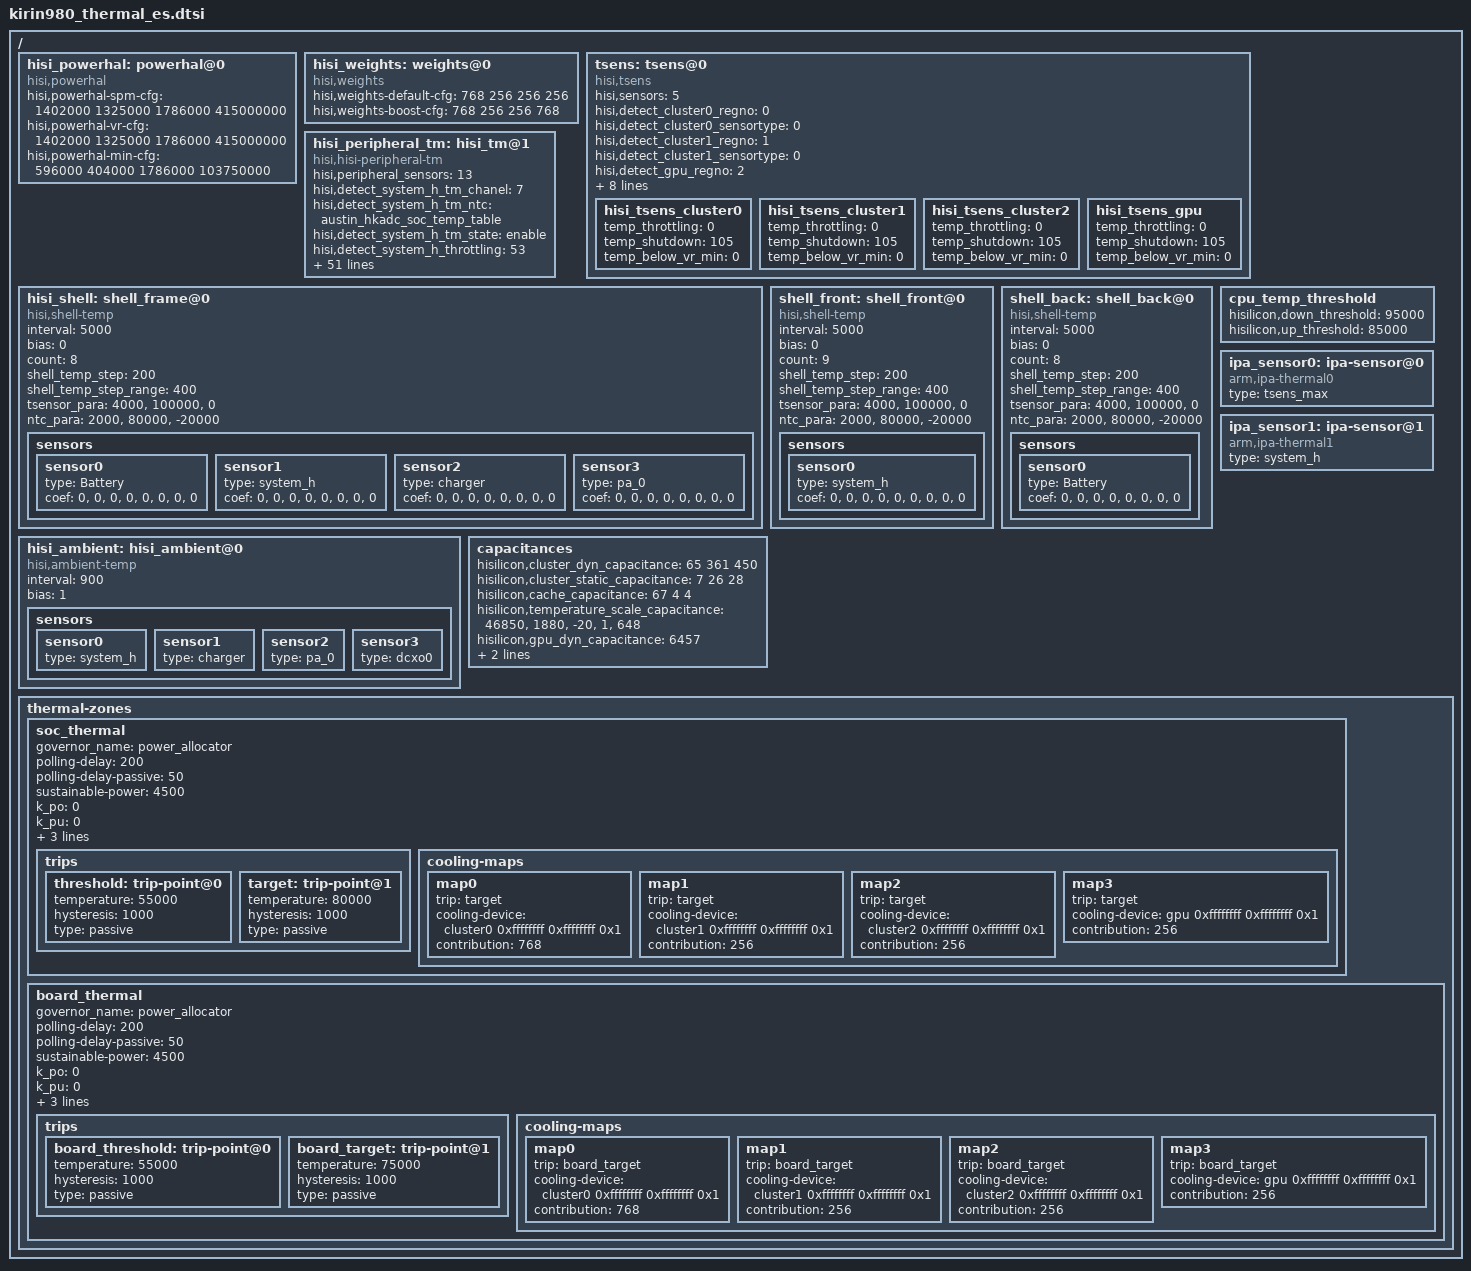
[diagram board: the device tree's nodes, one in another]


  /{
		hisi_powerhal: powerhal@0 {
			compatible = "hisi,powerhal";
			/*CPU_L, CPU_M, CPU_B, GPU*/
			hisi,powerhal-spm-cfg = <1402000 1325000 1786000 415000000>;
			hisi,powerhal-vr-cfg = <1402000 1325000 1786000 415000000>;
			hisi,powerhal-min-cfg = <596000 404000 1786000 103750000>;
		};

		hisi_weights: weights@0 {
			compatible = "hisi,weights";
			/*IPA_CLUSTER0, IPA_CLUSTER1, IPA_CLUSTER2, GPU*/
			hisi,weights-default-cfg = <768 256 256 256>;
			hisi,weights-boost-cfg = <768 256 256 768>;
		};

		tsens: tsens@0{
			compatible = "hisi,tsens";
			hisi,sensors = <5>;
			/*sensortype, 0:Tsensor, 1:PVTsensor */
			hisi,detect_cluster0_regno = <0>;
			hisi,detect_cluster0_sensortype = <0>;
			hisi,detect_cluster1_regno = <1>;
			hisi,detect_cluster1_sensortype = <0>;
			hisi,detect_gpu_regno = <2>;
			hisi,detect_gpu_sensortype = <1>;
			hisi,detect_modem_regno = <3>;
			hisi,detect_modem_sensortype = <0>;
			hisi,detect_ddr_regno = <0xff>;
			hisi,tsensor_adc_start_value = <109>;
			hisi,tsensor_adc_end_value = <907>;
			hisi,pvtsensor_adc_start_value = <500>;
			hisi,pvtsensor_adc_end_value = <851>;
			hisi_tsens_cluster0 {
				temp_throttling = <0>;
				temp_shutdown = <105>;
				temp_below_vr_min = <0>;
			};

			hisi_tsens_cluster1 {
				temp_throttling = <0>;
				temp_shutdown = <105>;
				temp_below_vr_min = <0>;
			};
			hisi_tsens_cluster2 {
				temp_throttling = <0>;
				temp_shutdown = <105>;
				temp_below_vr_min = <0>;
			};
			hisi_tsens_gpu {
				temp_throttling = <0>;
				temp_shutdown = <105>;
				temp_below_vr_min = <0>;
			};
		};

		hisi_peripheral_tm: hisi_tm@1 {
			compatible = "hisi,hisi-peripheral-tm";
			hisi,peripheral_sensors = <13>;

			hisi,detect_system_h_tm_chanel = <7>;
			hisi,detect_system_h_tm_ntc = "austin_hkadc_soc_temp_table";
			hisi,detect_system_h_tm_state = "enable";
			hisi,detect_system_h_throttling = <53>;
			hisi,detect_system_h_shutdown = <55>;
			hisi,detect_system_h_below_vr_min = <53>;
			hisi,detect_system_h_over_skin = <12>;

			hisi,detect_flash_led_tm_chanel = <13>;
			hisi,detect_flash_led_tm_ntc = "austin_hkadc_soc_temp_table";
			hisi,detect_flash_led_tm_state = "enable";

			hisi,detect_charger_tm_chanel = <4>;
			hisi,detect_charger_tm_ntc = "austin_hkadc_soc_temp_table";
			hisi,detect_charger_tm_state = "enable";

			hisi,detect_pa_0_tm_chanel = <5>;
			hisi,detect_pa_0_tm_ntc = "austin_hkadc_pa_temp_table";
			hisi,detect_pa_0_tm_state = "enable";

			hisi,detect_pa_1_tm_chanel = <6>;
			hisi,detect_pa_1_tm_ntc = "austin_hkadc_pa_temp_table";
			hisi,detect_pa_1_tm_state = "enable";

			hisi,detect_dcxo0_tm_chanel = <15>;
			hisi,detect_dcxo0_tm_ntc = "austin_hkadc_adc_temp_table";
			hisi,detect_dcxo0_tm_state = "enable";

			hisi,detect_shell_tm_chanel = <7>;
			hisi,detect_shell_tm_ntc = "austin_hkadc_soc_temp_table";
			hisi,detect_shell_tm_state = "disable";

			hisi,detect_charger1_tm_chanel = <4>;
			hisi,detect_charger1_tm_ntc = "austin_hkadc_soc_temp_table";
			hisi,detect_charger1_tm_state = "disable";

			hisi,detect_rfboard_tm_chanel = <0>;
			hisi,detect_rfboard_tm_ntc = "austin_hkadc_soc_temp_table";
			hisi,detect_rfboard_tm_state = "disable";

			hisi,detect_usb_tm_chanel = <0>;
			hisi,detect_usb_tm_ntc = "austin_hkadc_soc_temp_table";
			hisi,detect_usb_tm_state = "disable";

			hisi,detect_wireless_tm_chanel = <0>;
			hisi,detect_wireless_tm_ntc = "austin_hkadc_soc_temp_table";
			hisi,detect_wireless_tm_state = "disable";

			hisi,detect_ir_tm_chanel = <0>;
			hisi,detect_ir_tm_ntc = "austin_hkadc_soc_temp_table";
			hisi,detect_ir_tm_state = "disable";

			hisi,detect_dot_tm_chanel = <0>;
			hisi,detect_dot_tm_ntc = "austin_hkadc_soc_temp_table";
			hisi,detect_dot_tm_state = "disable";

			status = "ok";
		};

		hisi_shell: shell_frame@0 {
			compatible = "hisi,shell-temp";
			interval = <5000>;
			bias = <0>;
			count = <8>;
			shell_temp_step = <200>;
			shell_temp_step_range = <400>;
			tsensor_para = "4000","100000","0";
			ntc_para = "2000","80000","-20000";
			status = "ok";
			sensors {
				sensor0 {
					type = "Battery";
					coef = "0","0","0","0","0","0","0","0";
				};
				sensor1 {
					type = "system_h";
					coef = "0","0","0","0","0","0","0","0";
				};
				sensor2 {
					type = "charger";
					coef = "0","0","0","0","0","0","0","0";
				};
				sensor3 {
					type = "pa_0";
					coef = "0","0","0","0","0","0","0","0";
				};
			};
		};

		shell_front: shell_front@0 {
			compatible = "hisi,shell-temp";
			interval = <5000>;
			bias = <0>;
			count = <9>;
			shell_temp_step = <200>;
			shell_temp_step_range = <400>;
			tsensor_para = "4000","100000","0";
			ntc_para = "2000","80000","-20000";
			status = "ok";
			sensors {
				sensor0 {
					type = "system_h";
					coef = "0","0","0","0","0","0","0","0","0";
				};
			};
		};

		shell_back: shell_back@0 {
			compatible = "hisi,shell-temp";
			interval = <5000>;
			bias = <0>;
			count = <8>;
			shell_temp_step = <200>;
			shell_temp_step_range = <400>;
			tsensor_para = "4000","100000","0";
			ntc_para = "2000","80000","-20000";
			status = "ok";
			sensors {
				sensor0 {
					type = "Battery";
					coef = "0","0","0","0","0","0","0","0";
				};
			};
		};

		hisi_ambient: hisi_ambient@0 {
			compatible = "hisi,ambient-temp";
			interval = <900>;
			bias = <1>;
			status = "ok";
			sensors {
				sensor0 {
					type = "system_h";
				};
				sensor1 {
					type = "charger";
				};
				sensor2 {
					type = "pa_0";
				};
				sensor3 {
					type = "dcxo0";
				};
			};
		};

		cpu_temp_threshold {
			hisilicon,down_threshold = <95000>;
			hisilicon,up_threshold = <85000>;
		};

		capacitances {
			hisilicon,cluster_dyn_capacitance = <65 361 450>;/*little middle big*/
			hisilicon,cluster_static_capacitance = <7 26 28>;/*little middle big*/
			hisilicon,cache_capacitance = <67 4 4>;/*little middle big*/
			hisilicon,temperature_scale_capacitance = "46850","1880","-20","1","648"; /*temperature_scale_capacitance*/
			hisilicon,gpu_dyn_capacitance = <6457>;
			hisilicon,gpu_temp_scale_capacitance = "-49650","4688","-92","1","100";
		};

		ipa_sensor0: ipa-sensor@0 {
			type = "tsens_max";
			compatible = "arm,ipa-thermal0";
			#thermal-sensor-cells = <1>;
			status = "ok";
		};

		ipa_sensor1: ipa-sensor@1 {
			type = "system_h";
			compatible = "arm,ipa-thermal1";
			#thermal-sensor-cells = <1>;
			status = "ok";
		};

		thermal-zones {
			soc_thermal {
				governor_name = "power_allocator";
				polling-delay = <200>;
				polling-delay-passive = <50>;
				sustainable-power = <4500>;
				k_po = <0>;
				k_pu = <0>;
				k_i = <10>;
				integral_cutoff = <8>;
				thermal-sensors = <&ipa_sensor0 255>;

				trips {
					threshold: trip-point@0 {
						temperature = <55000>;
						hysteresis = <1000>;
						type = "passive";
					};
					target: trip-point@1 {
						temperature = <80000>;
						hysteresis = <1000>;
						type = "passive";
					};
				};

				cooling-maps {
					map0 {
						trip = <&target>;
						cooling-device = <&cluster0 0xffffffff 0xffffffff 0x1>;
						contribution = <768>;
					};
					map1 {
						trip = <&target>;
						cooling-device = <&cluster1 0xffffffff 0xffffffff 0x1>;
						contribution = <256>;
					};
					map2 {
						trip = <&target>;
						cooling-device = <&cluster2 0xffffffff 0xffffffff 0x1>;
						contribution = <256>;
					};
					map3 {
						trip = <&target>;
						cooling-device = <&gpu 0xffffffff 0xffffffff 0x1>;
						contribution = <256>;
					};
				};
			};

			board_thermal {
				governor_name = "power_allocator";
				polling-delay = <200>;
				polling-delay-passive = <50>;
				sustainable-power = <4500>;
				k_po = <0>;
				k_pu = <0>;
				k_i = <1>;
				integral_cutoff = <8>;
				thermal-sensors = <&ipa_sensor1 0>;

				trips {
					board_threshold: trip-point@0 {
							temperature = <55000>;
							hysteresis = <1000>;
							type = "passive";
						};
					board_target: trip-point@1 {
							temperature = <75000>;
							hysteresis = <1000>;
							type = "passive";
						};
				};
				cooling-maps {
					map0 {
						trip = <&board_target>;
						cooling-device = <&cluster0 0xffffffff 0xffffffff 0x1>;
						contribution = <768>;
					};
					map1 {
						trip = <&board_target>;
						cooling-device = <&cluster1 0xffffffff 0xffffffff 0x1>;
						contribution = <256>;
					};
					map2 {
						trip = <&board_target>;
						cooling-device = <&cluster2 0xffffffff 0xffffffff 0x1>;
						contribution = <256>;
					};
					map3 {
						trip = <&board_target>;
						cooling-device = <&gpu 0xffffffff 0xffffffff 0x1>;
						contribution = <256>;
					};
				};
			};
		};
	};
